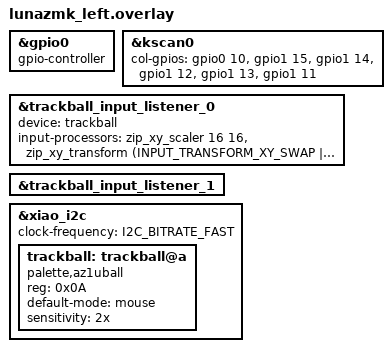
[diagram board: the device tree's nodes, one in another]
/*
 * Copyright (c) 2020 Pete Johanson
 *
 * SPDX-License-Identifier: MIT
 */

#include "lunazmk.dtsi"
#include <input/processors.dtsi>
#include <dt-bindings/zmk/input_transform.h>
&gpio0 {
    #interrupt-cells = <2>;
    gpio-controller;
};

&kscan0 {
	col-gpios
		= <&gpio0 10 GPIO_ACTIVE_HIGH>   //Col0
		, <&gpio1 15 GPIO_ACTIVE_HIGH>   //Col1
		, <&gpio1 14 GPIO_ACTIVE_HIGH>   //Col2
		, <&gpio1 12 GPIO_ACTIVE_HIGH>   //Col3
		, <&gpio1 13 GPIO_ACTIVE_HIGH>   //Col4
		, <&gpio1 11 GPIO_ACTIVE_HIGH>   //Col5
		;
};

&trackball_input_listener_0 {
    status = "okay";
    device = <&trackball>;
    input-processors = <&zip_xy_scaler 16 16>,<&zip_xy_transform (INPUT_TRANSFORM_XY_SWAP | INPUT_TRANSFORM_X_INVERT)>;
};

&trackball_input_listener_1 {
    status = "okay";
};

&xiao_i2c {
    status = "okay";
    clock-frequency = <I2C_BITRATE_FAST>;
    trackball: trackball@a {
        compatible = "palette,az1uball";
        reg = <0x0A>;
        status = "okay";
        default-mode = "mouse";
        sensitivity = "2x";
    };
};

